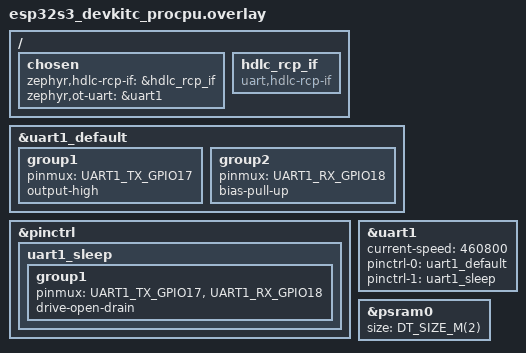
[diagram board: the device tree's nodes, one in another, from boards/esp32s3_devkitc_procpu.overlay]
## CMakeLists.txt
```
# SPDX-License-Identifier: Apache-2.0

cmake_minimum_required(VERSION 3.28.0)

find_package(Zephyr REQUIRED HINTS $ENV{ZEPHYR_BASE})
project(ot_coap)

target_include_directories(app PRIVATE src)

target_sources(app PRIVATE
    src/main.c
    src/coap_utils.c
    src/coap_shell.c
)

target_sources_ifdef(CONFIG_OT_COAP_SAMPLE_LED app PRIVATE src/led.c)
target_sources_ifdef(CONFIG_OT_COAP_SAMPLE_SW app PRIVATE src/button.c)

include(${ZEPHYR_BASE}/samples/net/common/common.cmake)

set(gen_dir ${ZEPHYR_BINARY_DIR}/include/generated/)
```

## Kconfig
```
# Config options for OpenThread Border CoAP sample app

# Copyright (c) 2024 Alexandre Bailon
# SPDX-License-Identifier: Apache-2.0

mainmenu "OpenThread CoAP Sample"

menu "Application configuration"

config OT_COAP_SAMPLE_SERVER
	bool "Build the sample CoAP server application"

config OT_COAP_SAMPLE_LED
	bool "Enable LED support"
	default y

config OT_COAP_SAMPLE_SW
	bool "Enable switch support"
	default y

endmenu

source "Kconfig.zephyr"
```

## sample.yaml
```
common:
  harness: net
  tags:
    - net
    - openthread
  depends_on: openthread
  min_flash: 140
  build_only: true
  platform_allow:
    - cc1352p7_lp
    - nrf52840dk/nrf52840
sample:
  description: Runs the OpenThread stack as FTD with CoAP
  name: OpenThread FTD CoAP
tests:
  sample.net.openthread.ftd.coap.client: {}
  sample.net.openthread.ftd.coap.server:
    extra_configs:
      - CONFIG_OT_COAP_SAMPLE_SERVER=y
```

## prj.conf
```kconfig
CONFIG_NETWORKING=y
CONFIG_NET_L2_OPENTHREAD=y
CONFIG_OPENTHREAD_COAP=y
CONFIG_OPENTHREAD_SLAAC=y
CONFIG_JSON_LIBRARY=y

# Logging
CONFIG_LOG=y
CONFIG_LOG_MAX_LEVEL=1
CONFIG_LOG_MODE_MINIMAL=n
CONFIG_BOOT_BANNER=y
CONFIG_LOG_BACKEND_UART=y

# Kernel options
CONFIG_MAIN_STACK_SIZE=2560
CONFIG_INIT_STACKS=y

# Add features required for FTD CLI
CONFIG_SHELL=y
CONFIG_OPENTHREAD_SHELL=y
CONFIG_OPENTHREAD_PING_SENDER=y

# Network config
CONFIG_OPENTHREAD_PANID=4660
CONFIG_OPENTHREAD_XPANID="11:11:11:11:22:22:22:22"
CONFIG_OPENTHREAD_NETWORKKEY="00:11:22:33:44:55:66:77:88:99:aa:bb:cc:dd:ee:ff"
CONFIG_OPENTHREAD_CHANNEL=15
CONFIG_OPENTHREAD_NETWORK_NAME="OpenThreadDemo"

# Use NVS as settings backend
CONFIG_NVS=y
```

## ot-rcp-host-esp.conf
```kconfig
#
# Copyright (c) 2026 Espressif Systems (Shanghai) Co., Ltd.
#

CONFIG_SOC_FAMILY_ESPRESSIF_SPIRAM=y
CONFIG_SHARED_MULTI_HEAP=y

# lib & os
CONFIG_EVENTS=y

# CPP library
CONFIG_CPP=y

# Enable Openthread RCP host interface
CONFIG_IEEE802154=n
CONFIG_HDLC_RCP_IF=y
CONFIG_OPENTHREAD_MANUAL_START=y
CONFIG_OPENTHREAD_RCP_RESTORATION_MAX_COUNT=10
CONFIG_OPENTHREAD_EXTERNAL_HEAP_SHARED_MULTI_HEAP=y
CONFIG_OPENTHREAD_MESSAGE_POOL_CUSTOM_SECTION=y
```

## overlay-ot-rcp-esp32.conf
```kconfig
#
# Copyright 2025, Espressif Systems
#

# CONFIG_ESP_SPIRAM=y

# CPP library
# CONFIG_CPP=y

# Use NVS as settings backend
CONFIG_NVS=y

# Shell
# CONFIG_SHELL_ARGC_MAX=26
# CONFIG_SHELL_CMD_BUFF_SIZE=512
# CONFIG_SHELL_STACK_SIZE=5120

# Network shell
CONFIG_NET_SHELL=y
CONFIG_SHELL_GETOPT=y
CONFIG_SHELL_TAB=y
CONFIG_SHELL_TAB_AUTOCOMPLETION=y

# Enable Openthread RCP host interface
CONFIG_IEEE802154=n
CONFIG_HDLC_RCP_IF=y
CONFIG_OPENTHREAD_MANUAL_START=y
# CONFIG_OPENTHREAD_RCP_RESTORATION_MAX_COUNT=10

# Generic OT options
CONFIG_OPENTHREAD_THREAD_VERSION_1_4=y
CONFIG_OPENTHREAD_THREAD_STACK_SIZE=8192

# CONFIG_LOG_PROCESS_THREAD_STACK_SIZE=4096
```

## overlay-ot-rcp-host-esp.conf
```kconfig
#
# Copyright (c) 2026 Espressif Systems (Shanghai) Co., Ltd.
#

CONFIG_SOC_FAMILY_ESP32_SPIRAM=y
CONFIG_SHARED_MULTI_HEAP=y

# lib & os
CONFIG_EVENTS=y

# CPP library
CONFIG_CPP=y

# Enable Openthread RCP host interface
CONFIG_IEEE802154=n
CONFIG_HDLC_RCP_IF=y
CONFIG_OPENTHREAD_MANUAL_START=y
CONFIG_OPENTHREAD_RCP_RESTORATION_MAX_COUNT=10
CONFIG_OPENTHREAD_EXTERNAL_HEAP_SHARED_MULTI_HEAP=y
CONFIG_OPENTHREAD_MESSAGE_POOL_CUSTOM_SECTION=y
```

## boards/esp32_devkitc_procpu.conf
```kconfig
#
# Copyright (c) 2026 Espressif Systems (Shanghai) Co., Ltd.
#

CONFIG_SOC_FAMILY_ESP32_SPIRAM_HEAP_SIZE=524288
```

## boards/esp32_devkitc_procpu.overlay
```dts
/*
 *Copyright (c) 2026 Espressif Systems (Shanghai) Co., Ltd.
 *
 * SPDX-License-Identifier: Apache-2.0
 */

/ {
	chosen {
		zephyr,hdlc-rcp-if = &hdlc_rcp_if;
		zephyr,ot-uart = &uart1;
	};

	hdlc_rcp_if: hdlc_rcp_if {
		compatible = "uart,hdlc-rcp-if";
	};
};

&uart1 {
	current-speed = <460800>;
	status = "okay";
};

&psram0 {
	size = <DT_SIZE_M(2)>;
};
```

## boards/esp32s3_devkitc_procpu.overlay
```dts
/*
 *Copyright (c) 2026 Espressif Systems (Shanghai) Co., Ltd.
 *
 * SPDX-License-Identifier: Apache-2.0
 */

/ {
	chosen {
		zephyr,hdlc-rcp-if = &hdlc_rcp_if;
		zephyr,ot-uart = &uart1;
	};

	hdlc_rcp_if: hdlc_rcp_if {
		compatible = "uart,hdlc-rcp-if";
	};
};

&uart1_default {
	group1 {
		pinmux = <UART1_TX_GPIO17>;
		output-high;
	};

	group2 {
		pinmux = <UART1_RX_GPIO18>;
		bias-pull-up;
	};
};

&pinctrl {
	uart1_sleep: uart1_sleep {
		group1 {
			pinmux = <UART1_TX_GPIO17>,
				 <UART1_RX_GPIO18>;
			drive-open-drain;
		};
	};
};

&uart1 {
	current-speed = <460800>;
	pinctrl-0 = <&uart1_default>;
	pinctrl-1 = <&uart1_sleep>;
	pinctrl-names = "default", "sleep";
	status = "okay";
};

&psram0 {
	size = <DT_SIZE_M(2)>;
};
```

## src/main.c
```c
/*
 * Copyright (c) 2024 Alexandre Bailon
 *
 * SPDX-License-Identifier: Apache-2.0
 */

#include <zephyr/logging/log.h>
LOG_MODULE_REGISTER(coap);

#include <coap_utils.h>

#ifdef CONFIG_OT_COAP_SAMPLE_LED
#include "led.h"
#endif /* CONFIG_OT_COAP_SAMPLE_LED */

#ifdef CONFIG_OT_COAP_SAMPLE_SW
#include <zephyr/drivers/gpio.h>
#include "button.h"

/*
 * Get button configuration from the devicetree sw0 alias. This is mandatory.
 */
#define SW0_NODE DT_ALIAS(sw0)
#if !DT_NODE_HAS_STATUS_OKAY(SW0_NODE)
#error "Unsupported board: sw0 devicetree alias is not defined"
#endif
static const struct gpio_dt_spec button = GPIO_DT_SPEC_GET_OR(SW0_NODE, gpios, {0});
static struct gpio_callback button_cb_data;

void button_pressed(const struct device *dev, struct gpio_callback *cb, uint32_t pins)
{
	coap_led_set_state("ff03::1", 0, LED_MSG_STATE_TOGGLE);
}
#endif /* CONFIG_OT_COAP_SAMPLE_SW */

int main(void)
{
	int ret;

#ifdef CONFIG_OT_COAP_SAMPLE_SERVER
#ifdef CONFIG_OT_COAP_SAMPLE_LED
	coap_led_reg_rsc();
#endif /* CONFIG_OT_COAP_SAMPLE_LED */
#ifdef CONFIG_OT_COAP_SAMPLE_SW
	coap_btn_reg_rsc();
#endif /* CONFIG_OT_COAP_SAMPLE_SW */
#endif /* CONFIG_OT_COAP_SAMPLE_SERVER */

	ret = coap_init();
	if (ret) {
		return ret;
	}

#ifdef CONFIG_OT_COAP_SAMPLE_SW
	button_init(&button);

	gpio_init_callback(&button_cb_data, button_pressed, BIT(button.pin));
	gpio_add_callback_dt(&button, &button_cb_data);
#endif /*CONFIG_OT_COAP_SAMPLE_SW */

	return 0;
}
```

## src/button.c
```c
/*
 * Copyright (c) 2024 Alexandre Bailon
 *
 * SPDX-License-Identifier: Apache-2.0
 */

#include <zephyr/drivers/gpio.h>
#include <zephyr/logging/log.h>
LOG_MODULE_DECLARE(coap);

#include "coap_utils.h"
#include "button.h"

struct btn_rsc_data {
	const struct gpio_dt_spec gpio;
};

struct btn_rsc_ctx {
	struct btn_rsc_data *btn;
	int count;
};

static const struct json_obj_descr json_btn_state_descr[] = {
	JSON_OBJ_DESCR_PRIM(struct json_btn_state, btn_id, JSON_TOK_NUMBER),
	JSON_OBJ_DESCR_PRIM(struct json_btn_state, state, JSON_TOK_NUMBER),
};

static const struct json_obj_descr json_btn_get_descr[] = {
	JSON_OBJ_DESCR_PRIM(struct json_btn_get, device_id, JSON_TOK_STRING),
	JSON_OBJ_DESCR_OBJ_ARRAY(struct json_btn_get, btns, JSON_MAX_BTN, count,
				 json_btn_state_descr, ARRAY_SIZE(json_btn_state_descr)),
};

static K_SEM_DEFINE(btn_get_sem, 0, 1);

#ifdef CONFIG_OT_COAP_SAMPLE_SERVER
static int btn_handler_get(void *ctx, otMessage *msg, const otMessageInfo *msg_info)
{
	uint8_t buf[COAP_MAX_BUF_SIZE];
	struct btn_rsc_ctx *btn_ctx = ctx;

	struct json_btn_get btn_data = {
		.device_id = coap_device_id(),
	};

	for (int i = 0; i < btn_ctx->count; i++) {
		btn_data.btns[i].btn_id = i;
		btn_data.btns[i].state = gpio_pin_get_dt(&btn_ctx->btn[i].gpio);
	}
	btn_data.count = btn_ctx->count;

	json_obj_encode_buf(json_btn_get_descr, ARRAY_SIZE(json_btn_get_descr), &btn_data, buf,
			    COAP_MAX_BUF_SIZE);

	return coap_resp_send(msg, msg_info, buf, strlen(buf) + 1);
}

static void btn_handler(void *ctx, otMessage *msg, const otMessageInfo *msg_info)
{
	coap_req_handler(ctx, msg, msg_info, NULL, btn_handler_get);
}

#define DEFINE_BTN_CTX(node_id)                                                                    \
	{                                                                                          \
		.gpio = GPIO_DT_SPEC_GET(node_id, gpios),                                          \
	},

#define DEFINE_BTNS_CTX(inst, compat, ...) DT_FOREACH_CHILD(DT_INST(inst, compat), DEFINE_BTN_CTX)

static struct btn_rsc_data btn_rsc_data[] = {
	DT_COMPAT_FOREACH_STATUS_OKAY_VARGS(gpio_keys, DEFINE_BTNS_CTX)};

static struct btn_rsc_ctx btn_rsc_ctx = {
	.btn = btn_rsc_data,
	.count = ARRAY_SIZE(btn_rsc_data),
};

static otCoapResource btn_rsc = {
	.mUriPath = BTN_URI,
	.mHandler = btn_handler,
	.mContext = &btn_rsc_ctx,
	.mNext = NULL,
};

static int button_init_rsc(otCoapResource *rsc)
{
	int ret = 0;

	struct btn_rsc_ctx *btn_ctx = rsc->mContext;
	const struct gpio_dt_spec *gpio;

	LOG_INF("Initializing the buttons");
	for (int i = 0; i < btn_ctx->count; i++) {
		gpio = &btn_ctx->btn[i].gpio;
		ret = button_init(gpio);
		if (ret) {
			break;
		}
	}

	return ret;
}

void coap_btn_reg_rsc(void)
{
	otInstance *ot = openthread_get_default_instance();

	button_init_rsc(&btn_rsc);
	LOG_INF("Registering button rsc");
	otCoapAddResource(ot, &btn_rsc);
}
#endif /* CONFIG_OT_COAP_SAMPLE_SERVER */

int button_init(const struct gpio_dt_spec *gpio)
{
	int ret;

	if (!gpio_is_ready_dt(gpio)) {
		LOG_ERR("Error: button device %s is not ready\n", gpio->port->name);
		return -ENODEV;
	}

	ret = gpio_pin_configure_dt(gpio, GPIO_INPUT);
	if (ret != 0) {
		LOG_ERR("Error %d: failed to configure %s pin %d\n", ret, gpio->port->name,
			gpio->pin);
		return ret;
	}

	ret = gpio_pin_interrupt_configure_dt(gpio, GPIO_INT_EDGE_TO_ACTIVE);
	if (ret != 0) {
		LOG_ERR("Error %d: failed to configure interrupt on %s pin %d\n", ret,
			gpio->port->name, gpio->pin);
		return ret;
	}

	return 0;
}

static void coap_btn_get_state_cb(void *ctx, otMessage *msg, const otMessageInfo *msg_info,
				  otError error)
{
	uint8_t buf[COAP_MAX_BUF_SIZE];
	int len = COAP_MAX_BUF_SIZE;
	struct json_btn_get *btn = (struct json_btn_get *)ctx;
	int ret;

	ret = coap_get_data(msg, buf, &len);
	if (ret) {
		btn->count = 0;
		goto exit;
	}

	json_obj_parse(buf, len, json_btn_get_descr, ARRAY_SIZE(json_btn_get_descr), btn);
exit:
	k_sem_give(&btn_get_sem);
}

int coap_btn_get_state(const char *addr, int btn_id, int *state)
{
	struct json_btn_get btn;
	int ret;

	ret = coap_get_req_send(addr, BTN_URI, NULL, 0, coap_btn_get_state_cb, &btn);
	if (ret) {
		return ret;
	}

	ret = k_sem_take(&btn_get_sem, K_FOREVER);
	if (ret) {
		return ret;
	}

	if (btn_id >= btn.count) {
		return -ENODEV;
	}

	*state = btn.btns[btn_id].state;
	return ret;
}
```

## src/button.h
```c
/*
 * Copyright (c) 2024 Alexandre Bailon
 *
 * SPDX-License-Identifier: Apache-2.0
 */

#ifndef COAP_BUTTON_H
#define COAP_BUTTON_H

#include <zephyr/drivers/gpio.h>
#include <zephyr/data/json.h>

#define BTN_URI "sw"

#define BTN_MSG_STATE_OFF 0
#define BTN_MSG_STATE_ON  1

#define JSON_MAX_BTN 4

struct json_btn_state {
	int btn_id;
	int state;
};

struct json_btn_get {
	const char *device_id;
	struct json_btn_state btns[JSON_MAX_BTN];
	int count;
};

int button_init(const struct gpio_dt_spec *gpio);
int coap_btn_get_state(const char *addr, int led_id, int *state);

#ifdef CONFIG_OT_COAP_SAMPLE_SERVER
void coap_btn_reg_rsc(void);
#endif

#endif /* COAP_BUTTON_H */
```

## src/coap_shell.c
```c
/*
 * Copyright (c) 2024 Alexandre Bailon
 *
 * SPDX-License-Identifier: Apache-2.0
 */

#include <zephyr/shell/shell.h>

#include "led.h"
#include "button.h"

static int coap_cmd_led_set(const struct shell *sh, size_t argc, char **argv)
{
	int led_id;
	int led_state;
	const char *addr;
	int err = 0;

	led_id = shell_strtol(argv[1], 10, &err);
	if (err) {
		shell_error(sh, "Failed to get a valid LED id: %s", argv[1]);
		return err;
	}

	if (!strcmp(argv[2], "on")) {
		led_state = LED_MSG_STATE_ON;
	} else if (!strcmp(argv[2], "off")) {
		led_state = LED_MSG_STATE_OFF;
	} else if (!strcmp(argv[2], "toggle")) {
		led_state = LED_MSG_STATE_TOGGLE;
	} else {
		shell_error(sh, "Failed to get a valid LED state");
		return -EINVAL;
	}

	if (argc <= 3) {
		addr = "ff03::1";
	} else {
		addr = argv[3];
	}

	return coap_led_set_state(addr, led_id, led_state);
}

static int coap_cmd_led_get(const struct shell *sh, size_t argc, char **argv)
{
	int led_id;
	int led_state;
	const char *addr;
	int err = 0;

	led_id = shell_strtol(argv[1], 10, &err);
	if (err) {
		shell_error(sh, "Failed to get a valid LED id: %s", argv[1]);
		return err;
	}

	if (argc <= 3) {
		addr = "ff03::1";
	} else {
		addr = argv[3];
	}

	err = coap_led_get_state(addr, led_id, &led_state);
	if (err) {
		return err;
	}

	if (led_state == LED_MSG_STATE_ON) {
		shell_info(sh, "on");
	} else {
		shell_info(sh, "off");
	}

	return 0;
}

static int coap_cmd_btn_get(const struct shell *sh, size_t argc, char **argv)
{
	int btn_id;
	int btn_state;
	const char *addr;
	int err = 0;

	btn_id = shell_strtol(argv[1], 10, &err);
	if (err) {
		shell_error(sh, "Failed to get a valid button id: %s", argv[1]);
		return err;
	}

	if (argc <= 3) {
		addr = "ff03::1";
	} else {
		addr = argv[3];
	}

	err = coap_btn_get_state(addr, btn_id, &btn_state);
	if (err) {
		return err;
	}

	if (btn_state == BTN_MSG_STATE_ON) {
		shell_info(sh, "on");
	} else {
		shell_info(sh, "off");
	}

	return 0;
}

static const char coap_cmd_led_set_help[] =
	"Set a LED state using CoAP\n"
	"led set <led_id> <led_state> [addr]\n"
	"\tled_id: a number defining the LED to control from CoAP server\n"
	"\tled_state: on, off or toggle\n"
	"\taddr: the IPv6 address of CoAP server. If not defined, it will broadcast to all CoAP "
	"servers\n";

static const char coap_cmd_led_get_help[] =
	"Get a LED state using CoAP\n"
	"led get <led_id> [addr]\n"
	"\tled_id: a number defining the LED to get from CoAP server\n"
	"\taddr: the IPv6 address of CoAP server. If not defined, it "
	"will broadcast to all CoAP servers\n";

SHELL_STATIC_SUBCMD_SET_CREATE(
	coap_led_subcmd, SHELL_CMD_ARG(set, NULL, coap_cmd_led_set_help, coap_cmd_led_set, 3, 1),
	SHELL_CMD_ARG(get, NULL, coap_cmd_led_get_help, coap_cmd_led_get, 2, 1),
	SHELL_SUBCMD_SET_END);

static const char coap_cmd_btn_get_help[] =
	"Get a button state using CoAP\n"
	"btn get <btn_id> [addr]\n"
	"\tbtn_id: a number defining the button to get from CoAP server\n"
	"\taddr: the IPv6 address of CoAP server. If not defined, it "
	"will broadcast to all CoAP servers\n";

SHELL_STATIC_SUBCMD_SET_CREATE(coap_btn_subcmd,
			       SHELL_CMD_ARG(get, NULL, coap_cmd_btn_get_help, coap_cmd_btn_get, 2,
					     1),
			       SHELL_SUBCMD_SET_END);

SHELL_STATIC_SUBCMD_SET_CREATE(coap_subcmd,
			       SHELL_CMD(led, &coap_led_subcmd, "Manage a LED using CoAP", NULL),
			       SHELL_CMD(btn, &coap_btn_subcmd, "Manage a button using CoAP", NULL),
			       SHELL_SUBCMD_SET_END);

SHELL_CMD_REGISTER(ot_coap, &coap_subcmd, "CoAP sample client", NULL);
```

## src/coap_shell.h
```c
/*
 * Copyright (c) 2024 Alexandre Bailon
 *
 * SPDX-License-Identifier: Apache-2.0
 */
```

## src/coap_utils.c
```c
/*
 * Copyright (c) 2024 Alexandre Bailon
 *
 * SPDX-License-Identifier: Apache-2.0
 */

#include <errno.h>

#include <zephyr/logging/log.h>
LOG_MODULE_DECLARE(coap);

#include "coap_utils.h"
#include <openthread/platform/radio.h>

static uint8_t coap_buf[COAP_MAX_BUF_SIZE];
static uint8_t coap_dev_id[COAP_DEVICE_ID_SIZE];

#ifdef CONFIG_OT_COAP_SAMPLE_SERVER
static void coap_default_handler(void *context, otMessage *message,
				 const otMessageInfo *message_info)
{
	ARG_UNUSED(context);
	ARG_UNUSED(message);
	ARG_UNUSED(message_info);

	LOG_INF("Received CoAP message that does not match any request "
		"or resource");
}
#endif /* CONFIG_OT_COAP_SAMPLE_SERVER */

static int coap_req_send(const char *addr, const char *uri, uint8_t *buf, int len,
			 otCoapResponseHandler handler, void *ctx, otCoapCode code)
{
	otInstance *ot;
	otMessage *msg;
	otMessageInfo msg_info;
	otError err;
	int ret;

	ot = openthread_get_default_instance();
	if (!ot) {
		LOG_ERR("Failed to get an OpenThread instance");
		return -ENODEV;
	}

	memset(&msg_info, 0, sizeof(msg_info));
	otIp6AddressFromString(addr, &msg_info.mPeerAddr);
	msg_info.mPeerPort = OT_DEFAULT_COAP_PORT;

	msg = otCoapNewMessage(ot, NULL);
	if (!msg) {
		LOG_ERR("Failed to allocate a new CoAP message");
		return -ENOMEM;
	}

	otCoapMessageInit(msg, OT_COAP_TYPE_CONFIRMABLE, code);

	err = otCoapMessageAppendUriPathOptions(msg, uri);
	if (err != OT_ERROR_NONE) {
		LOG_ERR("Failed to append uri-path: %s", otThreadErrorToString(err));
		ret = -EBADMSG;
		goto err;
	}

	err = otCoapMessageSetPayloadMarker(msg);
	if (err != OT_ERROR_NONE) {
		LOG_ERR("Failed to set payload marker: %s", otThreadErrorToString(err));
		ret = -EBADMSG;
		goto err;
	}

	err = otMessageAppend(msg, buf, len);
	if (err != OT_ERROR_NONE) {
		LOG_ERR("Failed to set append payload to response: %s", otThreadErrorToString(err));
		ret = -EBADMSG;
		goto err;
	}

	err = otCoapSendRequest(ot, msg, &msg_info, handler, ctx);
	if (err != OT_ERROR_NONE) {
		LOG_ERR("Failed to send the request: %s", otThreadErrorToString(err));
		ret = -EIO; /* Find a better error code */
		goto err;
	}

	return 0;

err:
	otMessageFree(msg);
	return ret;
}

int coap_put_req_send(const char *addr, const char *uri, uint8_t *buf, int len,
		      otCoapResponseHandler handler, void *ctx)
{
	return coap_req_send(addr, uri, buf, len, handler, ctx, OT_COAP_CODE_PUT);
}

int coap_get_req_send(const char *addr, const char *uri, uint8_t *buf, int len,
		      otCoapResponseHandler handler, void *ctx)
{
	return coap_req_send(addr, uri, buf, len, handler, ctx, OT_COAP_CODE_GET);
}

int coap_resp_send(otMessage *req, const otMessageInfo *req_info, uint8_t *buf, int len)
{
	otInstance *ot;
	otMessage *resp;
	otCoapCode resp_code;
	otCoapType resp_type;
	otError err;
	int ret;

	ot = openthread_get_default_instance();
	if (!ot) {
		LOG_ERR("Failed to get an OpenThread instance");
		return -ENODEV;
	}

	resp = otCoapNewMessage(ot, NULL);
	if (!resp) {
		LOG_ERR("Failed to allocate a new CoAP message");
		return -ENOMEM;
	}

	switch (otCoapMessageGetType(req)) {
	case OT_COAP_TYPE_CONFIRMABLE:
		resp_type = OT_COAP_TYPE_ACKNOWLEDGMENT;
		break;
	case OT_COAP_TYPE_NON_CONFIRMABLE:
		resp_type = OT_COAP_TYPE_NON_CONFIRMABLE;
		break;
	default:
		LOG_ERR("Invalid message type");
		ret = -EINVAL;
		goto err;
	}

	switch (otCoapMessageGetCode(req)) {
	case OT_COAP_CODE_GET:
		resp_code = OT_COAP_CODE_CONTENT;
		break;
	case OT_COAP_CODE_PUT:
		resp_code = OT_COAP_CODE_CHANGED;
		break;
	default:
		LOG_ERR("Invalid message code");
		ret = -EINVAL;
		goto err;
	}

	err = otCoapMessageInitResponse(resp, req, resp_type, resp_code);
	if (err != OT_ERROR_NONE) {
		LOG_ERR("Failed to initialize the response: %s", otThreadErrorToString(err));
		ret = -EBADMSG;
		goto err;
	}

	err = otCoapMessageSetPayloadMarker(resp);
	if (err != OT_ERROR_NONE) {
		LOG_ERR("Failed to set payload marker: %s", otThreadErrorToString(err));
		ret = -EBADMSG;
		goto err;
	}

	err = otMessageAppend(resp, buf, len);
	if (err != OT_ERROR_NONE) {
		LOG_ERR("Failed to set append payload to response: %s", otThreadErrorToString(err));
		ret = -EBADMSG;
		goto err;
	}

	err = otCoapSendResponse(ot, resp, req_info);
	if (err != OT_ERROR_NONE) {
		LOG_ERR("Failed to send the response: %s", otThreadErrorToString(err));
		ret = -EIO;
		goto err;
	}

	return 0;

err:
	otMessageFree(resp);
	return ret;
}

int coap_req_handler(void *ctx, otMessage *msg, const otMessageInfo *msg_info,
		     coap_req_handler_put put_fn, coap_req_handler_get get_fn)
{
	otCoapCode msg_code = otCoapMessageGetCode(msg);
	otCoapType msg_type = otCoapMessageGetType(msg);
	int ret;

	if (msg_type != OT_COAP_TYPE_CONFIRMABLE && msg_type != OT_COAP_TYPE_NON_CONFIRMABLE) {
		return -EINVAL;
	}

	if (msg_code == OT_COAP_CODE_PUT && put_fn) {
		int len = otMessageGetLength(msg) - otMessageGetOffset(msg);

		otMessageRead(msg, otMessageGetOffset(msg), coap_buf, len);
		ret = put_fn(ctx, coap_buf, len);
		if (ret) {
			return ret;
		}

		if (msg_type == OT_COAP_TYPE_CONFIRMABLE) {
			ret = get_fn(ctx, msg, msg_info);
		}

		return ret;
	}

	if (msg_code == OT_COAP_CODE_GET) {
		return get_fn(ctx, msg, msg_info);
	}

	return -EINVAL;
}

const char *coap_device_id(void)
{
	otInstance *ot = openthread_get_default_instance();
	otExtAddress eui64;
	int i;

	if (coap_dev_id[0] != '\0') {
		return coap_dev_id;
	}

	otPlatRadioGetIeeeEui64(ot, eui64.m8);
	for (i = 0; i < 8; i++) {
		if (i * 2 >= COAP_DEVICE_ID_SIZE) {
			i = COAP_DEVICE_ID_SIZE - 1;
			break;
		}
		sprintf(coap_dev_id + i * 2, "%02x", eui64.m8[i]);
	}
	coap_dev_id[i * 2] = '\0';

	return coap_dev_id;
}

int coap_get_data(otMessage *msg, void *buf, int *len)
{
	int coap_len = otMessageGetLength(msg) - otMessageGetOffset(msg);

	if (coap_len > *len) {
		return -ENOMEM;
	}

	*len = coap_len;
	otMessageRead(msg, otMessageGetOffset(msg), buf, coap_len);

	return 0;
}

int coap_init(void)
{
	otError err;
	otInstance *ot;

#ifdef CONFIG_OT_COAP_SAMPLE_SERVER
	LOG_INF("Initializing OpenThread CoAP server");
#else  /* CONFIG_OT_COAP_SAMPLE_SERVER */
	LOG_INF("Initializing OpenThread CoAP client");
#endif /* CONFIG_OT_COAP_SAMPLE_SERVER */
	ot = openthread_get_default_instance();
	if (!ot) {
		LOG_ERR("Failed to get an OpenThread instance");
		return -ENODEV;
	}

#ifdef CONFIG_OT_COAP_SAMPLE_SERVER
	otCoapSetDefaultHandler(ot, coap_default_handler, NULL);
#endif /* CONFIG_OT_COAP_SAMPLE_SERVER */

	err = otCoapStart(ot, OT_DEFAULT_COAP_PORT);
	if (err != OT_ERROR_NONE) {
		LOG_ERR("Cannot start CoAP: %s", otThreadErrorToString(err));
		return -EBADMSG;
	}

	return 0;
}
```

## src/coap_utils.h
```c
/*
 * Copyright (c) 2024 Alexandre Bailon
 *
 * SPDX-License-Identifier: Apache-2.0
 */

#ifndef COAP_UTILS_H
#define COAP_UTILS_H

#include <zephyr/net/openthread.h>
#include <openthread/coap.h>

#define COAP_MAX_BUF_SIZE   128
#define COAP_DEVICE_ID_SIZE 25

typedef int (*coap_req_handler_put)(void *ctx, uint8_t *buf, int size);
typedef int (*coap_req_handler_get)(void *ctx, otMessage *msg, const otMessageInfo *msg_info);

int coap_init(void);
int coap_req_handler(void *ctx, otMessage *msg, const otMessageInfo *msg_info,
		     coap_req_handler_put put_fn, coap_req_handler_get get_fn);
int coap_resp_send(otMessage *req, const otMessageInfo *req_info, uint8_t *buf, int len);
int coap_put_req_send(const char *addr, const char *uri, uint8_t *buf, int len,
		      otCoapResponseHandler handler, void *ctx);
int coap_get_req_send(const char *addr, const char *uri, uint8_t *buf, int len,
		      otCoapResponseHandler handler, void *ctx);
const char *coap_device_id(void);
int coap_get_data(otMessage *msg, void *buf, int *len);

#endif /* COAP_UTILS_H */
```

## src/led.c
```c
/*
 * Copyright (c) 2024 Alexandre Bailon
 *
 * SPDX-License-Identifier: Apache-2.0
 */

#include <zephyr/drivers/gpio.h>
#include <zephyr/logging/log.h>
LOG_MODULE_DECLARE(coap);

#include "coap_utils.h"
#include "led.h"

#ifdef CONFIG_OT_COAP_SAMPLE_SERVER
struct led_rsc_data {
	const struct gpio_dt_spec gpio;
	int state;
};

struct led_rsc_ctx {
	struct led_rsc_data *led;
	int count;
};
#endif

static const struct json_obj_descr json_led_state_descr[] = {
	JSON_OBJ_DESCR_PRIM(struct json_led_state, led_id, JSON_TOK_NUMBER),
	JSON_OBJ_DESCR_PRIM(struct json_led_state, state, JSON_TOK_NUMBER),
};

static const struct json_obj_descr json_led_get_descr[] = {
	JSON_OBJ_DESCR_PRIM(struct json_led_get, device_id, JSON_TOK_STRING),
	JSON_OBJ_DESCR_OBJ_ARRAY(struct json_led_get, leds, JSON_MAX_LED, count,
				 json_led_state_descr, ARRAY_SIZE(json_led_state_descr)),
};

K_SEM_DEFINE(led_get_sem, 0, 1);

#ifdef CONFIG_OT_COAP_SAMPLE_SERVER
static int led_init(otCoapResource *rsc)
{
	struct led_rsc_ctx *led_ctx = rsc->mContext;
	int ret;

	LOG_INF("Initializing the LED");
	for (int i = 0; i < led_ctx->count; i++) {
		struct led_rsc_data *led = &led_ctx->led[i];

		if (!gpio_is_ready_dt(&led->gpio)) {
			return -ENODEV;
		}

		ret = gpio_pin_configure_dt(&led->gpio, GPIO_OUTPUT);
		if (ret) {
			LOG_ERROR("Failed to configure the GPIO");
			return ret;
		}
	}

	return 0;
}

static int led_handler_put(void *ctx, uint8_t *buf, int size)
{
	struct json_led_state led_data;
	struct led_rsc_ctx *led_ctx = ctx;
	struct led_rsc_data *led;
	int ret = -EINVAL;

	json_obj_parse(buf, size, json_led_state_descr, ARRAY_SIZE(json_led_state_descr),
		       &led_data);

	if (led_data.led_id >= led_ctx->count) {
		LOG_ERROR("Invalid led id: %x", led_data.led_id);
		return -EINVAL;
	}
	led = &led_ctx->led[led_data.led_id];

	switch (led_data.state) {
	case LED_MSG_STATE_ON:
		ret = gpio_pin_set_dt(&led->gpio, 1);
		led->state = 1;
		break;
	case LED_MSG_STATE_OFF:
		ret = gpio_pin_set_dt(&led->gpio, 0);
		led->state = 0;
		break;
	case LED_MSG_STATE_TOGGLE:
		led->state = 1 - led->state;
		ret = gpio_pin_set_dt(&led->gpio, led->state);
		break;
	default:
		LOG_ERROR("Set an unsupported LED state: %x", led_data.state);
	}

	return ret;
}

static int led_handler_get(void *ctx, otMessage *msg, const otMessageInfo *msg_info)
{
	uint8_t buf[COAP_MAX_BUF_SIZE];
	struct led_rsc_ctx *led_ctx = ctx;

	struct json_led_get led_data = {
		.device_id = coap_device_id(),
	};

	for (int i = 0; i < led_ctx->count; i++) {
		led_data.leds[i].led_id = i;
		led_data.leds[i].state = led_ctx->led[i].state;
	}
	led_data.count = led_ctx->count;

	json_obj_encode_buf(json_led_get_descr, ARRAY_SIZE(json_led_get_descr), &led_data, buf,
			    COAP_MAX_BUF_SIZE);

	return coap_resp_send(msg, msg_info, buf, strlen(buf) + 1);
}

static void led_handler(void *ctx, otMessage *msg, const otMessageInfo *msg_info)
{
	coap_req_handler(ctx, msg, msg_info, led_handler_put, led_handler_get);
}

#define DEFINE_LED_CTX(node_id)                                                                    \
	{                                                                                          \
		.gpio = GPIO_DT_SPEC_GET(node_id, gpios),                                          \
		.state = 0,                                                                        \
	},

#define DEFINE_LEDS_CTX(inst, compat, ...) DT_FOREACH_CHILD(DT_INST(inst, compat), DEFINE_LED_CTX)

static struct led_rsc_data led_rsc_data[] = {
	DT_COMPAT_FOREACH_STATUS_OKAY_VARGS(gpio_leds, DEFINE_LEDS_CTX)};

static struct led_rsc_ctx led_rsc_ctx = {
	.led = led_rsc_data,
	.count = ARRAY_SIZE(led_rsc_data),
};

static otCoapResource led_rsc = {
	.mUriPath = LED_URI,
	.mHandler = led_handler,
	.mContext = &led_rsc_ctx,
	.mNext = NULL,
};

void coap_led_reg_rsc(void)
{
	otInstance *ot = openthread_get_default_instance();

	LOG_INF("Registering LED rsc");
	led_init(&led_rsc);
	otCoapAddResource(ot, &led_rsc);
}
#endif /* CONFIG_OT_COAP_SAMPLE_SERVER */

static void coap_led_send_req_cb(void *ctx, otMessage *msg, const otMessageInfo *msg_info,
				 otError error)
{
}

int coap_led_set_state(const char *addr, int led_id, int state)
{
	uint8_t buf[COAP_MAX_BUF_SIZE];

	struct json_led_state led_data = {
		.led_id = led_id,
		.state = state,
	};

	json_obj_encode_buf(json_led_state_descr, ARRAY_SIZE(json_led_state_descr), &led_data, buf,
			    COAP_MAX_BUF_SIZE);

	return coap_put_req_send(addr, LED_URI, buf, strlen(buf) + 1, coap_led_send_req_cb, NULL);
}

static void coap_led_get_state_cb(void *ctx, otMessage *msg, const otMessageInfo *msg_info,
				  otError error)
{
	uint8_t buf[COAP_MAX_BUF_SIZE];
	int len = COAP_MAX_BUF_SIZE;
	struct json_led_get *led = (struct json_led_get *)ctx;
	int ret;

	ret = coap_get_data(msg, buf, &len);
	if (ret) {
		led->count = 0;
		goto exit;
	}

	json_obj_parse(buf, len, json_led_get_descr, ARRAY_SIZE(json_led_get_descr), led);
exit:
	k_sem_give(&led_get_sem);
}

int coap_led_get_state(const char *addr, int led_id, int *state)
{
	struct json_led_get led;
	int ret;

	ret = coap_get_req_send(addr, LED_URI, NULL, 0, coap_led_get_state_cb, &led);
	if (ret) {
		return ret;
	}

	ret = k_sem_take(&led_get_sem, K_FOREVER);
	if (ret) {
		return ret;
	}

	if (led_id >= led.count) {
		return -ENODEV;
	}

	*state = led.leds[led_id].state;
	return ret;
}
```

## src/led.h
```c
/*
 * Copyright (c) 2024 Alexandre Bailon
 *
 * SPDX-License-Identifier: Apache-2.0
 */

#ifndef COAP_LED_H
#define COAP_LED_H

#include <zephyr/data/json.h>

#define LED_URI "led"

#define LED_MSG_STATE_OFF    0
#define LED_MSG_STATE_ON     1
#define LED_MSG_STATE_TOGGLE 2

#define JSON_MAX_LED 4

struct json_led_state {
	int led_id;
	int state;
};

struct json_led_get {
	const char *device_id;
	struct json_led_state leds[JSON_MAX_LED];
	int count;
};

int coap_led_set_state(const char *addr, int led_id, int state);
int coap_led_get_state(const char *addr, int led_id, int *state);

#ifdef CONFIG_OT_COAP_SAMPLE_SERVER
void coap_led_reg_rsc(void);
#endif /* CONFIG_OT_COAP_SAMPLE_SERVER */

#endif /* COAP_LED_H */
```
